# STM32MP157 register map
File version: 1.6
CPU: CM4 r0p1, little endian, no MPU, FPU, 4 interrupt priority bits
Registers are 32-bit, read-write, reset 0x0 unless marked. A register's access mark holds for its fields unless they carry their own. Offsets are from the block's base; [hi:lo] are bit positions; 'fields as' and 'values as' point back to an identical list.

## TIM12
Base 0x40006000
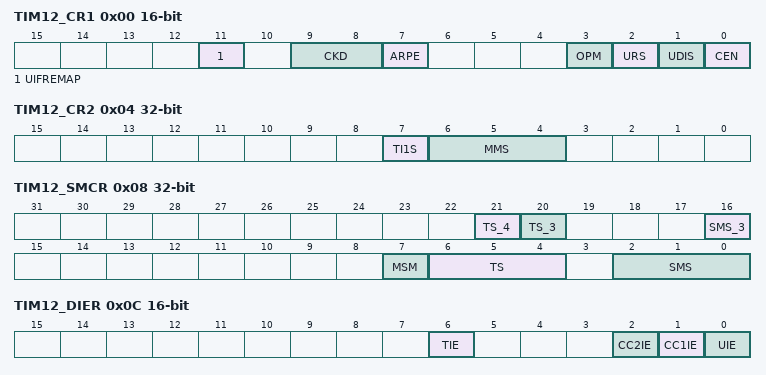
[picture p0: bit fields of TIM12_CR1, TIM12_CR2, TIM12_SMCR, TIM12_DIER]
0x00 TIM12_CR1 16-bit — TIM12 control register 1
  [11] UIFREMAP, [9:8] CKD, [7] ARPE, [3] OPM, [2] URS, [1] UDIS, [0] CEN
0x04 TIM12_CR2 — TIM12 control register 2
  [7] TI1S, [6:4] MMS
0x08 TIM12_SMCR — TIM12 slave mode control register
  [21] TS_4, [20] TS_3, [16] SMS_3, [7] MSM, [6:4] TS, [2:0] SMS
0x0C TIM12_DIER 16-bit — TIM12 interrupt enable register
  [6] TIE, [2] CC2IE, [1] CC1IE, [0] UIE
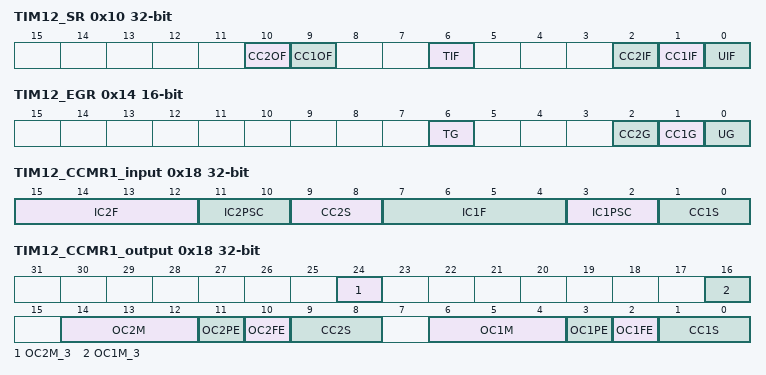
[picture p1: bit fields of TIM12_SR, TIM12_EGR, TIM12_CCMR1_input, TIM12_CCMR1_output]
0x10 TIM12_SR — TIM12 status register
  [10] CC2OF, [9] CC1OF, [6] TIF, [2] CC2IF, [1] CC1IF, [0] UIF
0x14 TIM12_EGR 16-bit wo — TIM12 event generation register
  [6] TG, [2] CC2G, [1] CC1G, [0] UG
0x18 TIM12_CCMR1_input — TIM12 capture/compare mode register 1
  [15:12] IC2F, [11:10] IC2PSC, [9:8] CC2S, [7:4] IC1F, [3:2] IC1PSC, [1:0] CC1S
0x18 TIM12_CCMR1_output (alternate view of TIM12_CCMR1_input) — TIM12 capture/compare mode register 1
  [24] OC2M_3
  [16] OC1M_3
  [14:12] OC2M
  [11] OC2PE
  [10] OC2FE
  [9:8] CC2S
  [6:4] OC1M
  [3] OC1PE — OC1FE
  [2] OC1FE
  [1:0] CC1S
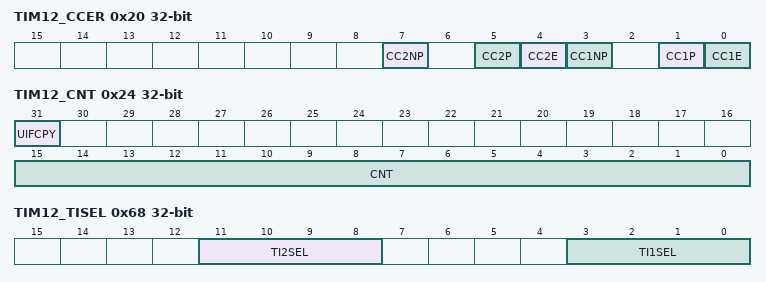
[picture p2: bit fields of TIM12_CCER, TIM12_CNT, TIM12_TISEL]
0x20 TIM12_CCER — TIM12 capture/compare enable register
  [7] CC2NP, [5] CC2P, [4] CC2E, [3] CC1NP, [1] CC1P, [0] CC1E
0x24 TIM12_CNT access per field — TIM12 counter
  [31] UIFCPY ro, [15:0] CNT rw
0x28 TIM12_PSC 16-bit — TIM12 prescaler
0x2C TIM12_ARR 16-bit reset 0xFFFF — TIM12 auto-reload register
0x34 TIM12_CCR1 16-bit — TIM12 capture/compare register 1
0x38 TIM12_CCR2 16-bit — TIM12 capture/compare register 2
0x68 TIM12_TISEL — TIM12 timer input selection register
  [11:8] TI2SEL, [3:0] TI1SEL

## TIM13
Base 0x40007000
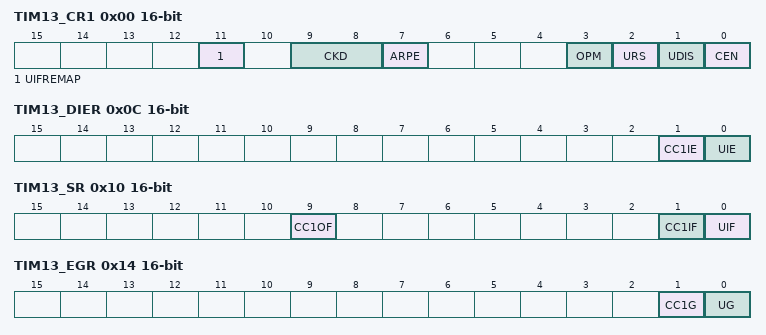
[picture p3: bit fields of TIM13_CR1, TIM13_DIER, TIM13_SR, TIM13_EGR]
0x00 TIM13_CR1 16-bit — TIM13 control register 1
  [11] UIFREMAP, [9:8] CKD, [7] ARPE, [3] OPM, [2] URS, [1] UDIS, [0] CEN
0x0C TIM13_DIER 16-bit — TIM13 Interrupt enable register
  [1] CC1IE, [0] UIE
0x10 TIM13_SR 16-bit — TIM13 status register
  [9] CC1OF, [1] CC1IF, [0] UIF
0x14 TIM13_EGR 16-bit wo — TIM13 event generation register
  [1] CC1G, [0] UG
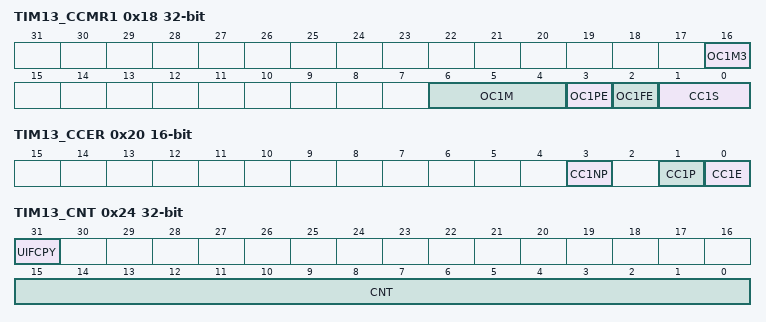
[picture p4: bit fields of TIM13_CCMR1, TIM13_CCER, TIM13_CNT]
0x18 TIM13_CCMR1 — The channels can be used in input (capture mode) or in output (compare mode). The direction of a channel is defined by configuring the corresponding CCxS bits. All the other bits of this register have a different function in input and in output mode. For a given bit, OCxx describes its function when the channel is configured in output, ICxx describes its function when the channel is configured in input. So one must take care that the same bit can have a different meaning for the input stage and for the output stage. Output compare mode
  [16] OC1M3, [6:4] OC1M, [3] OC1PE, [2] OC1FE, [1:0] CC1S
0x20 TIM13_CCER 16-bit — TIM13 capture/compare enable register
  [3] CC1NP, [1] CC1P, [0] CC1E
0x24 TIM13_CNT — TIM13 counter
  [31] UIFCPY, [15:0] CNT
0x28 TIM13_PSC 16-bit — TIM13 prescaler
0x2C TIM13_ARR 16-bit reset 0xFFFF — TIM13 auto-reload register
0x34 TIM13_CCR1 16-bit — TIM13 capture/compare register 1
0x68 TIM13_TISEL 16-bit — TIM13 timer input selection register
  [3:0] TI1SEL

## TIM14
Base 0x40008000
Registers as TIM13 (with TIM13 read as TIM14).

## TIM15
Base 0x44006000
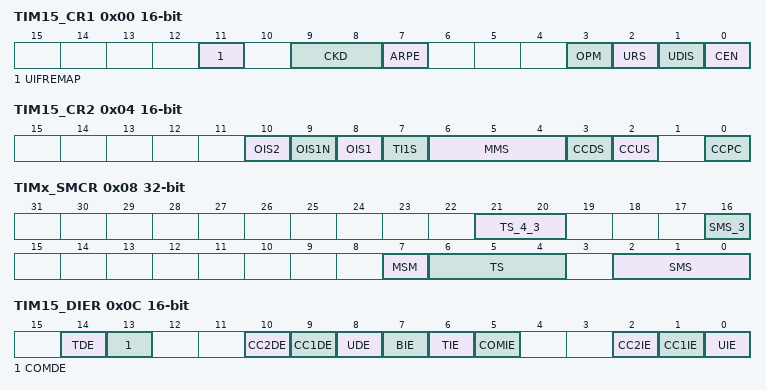
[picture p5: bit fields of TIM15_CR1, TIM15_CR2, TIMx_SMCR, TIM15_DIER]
0x00 TIM15_CR1 16-bit — TIM15 control register 1
  [11] UIFREMAP, [9:8] CKD, [7] ARPE, [3] OPM, [2] URS, [1] UDIS, [0] CEN
0x04 TIM15_CR2 16-bit — TIM15 control register 2
  [10] OIS2, [9] OIS1N, [8] OIS1, [7] TI1S, [6:4] MMS, [3] CCDS, [2] CCUS, [0] CCPC
0x08 TIMx_SMCR — slave mode control register
  [21:20] TS_4_3 — Trigger selection
  [16] SMS_3 — Slave mode selection - bit 3
  [7] MSM — Master/Slave mode
  [6:4] TS — Trigger selection
  [2:0] SMS — Slave mode selection
0x0C TIM15_DIER 16-bit — TIM15 DMA/interrupt enable register
  [14] TDE, [13] COMDE, [10] CC2DE, [9] CC1DE, [8] UDE, [7] BIE, [6] TIE, [5] COMIE, [2] CC2IE, [1] CC1IE, [0] UIE
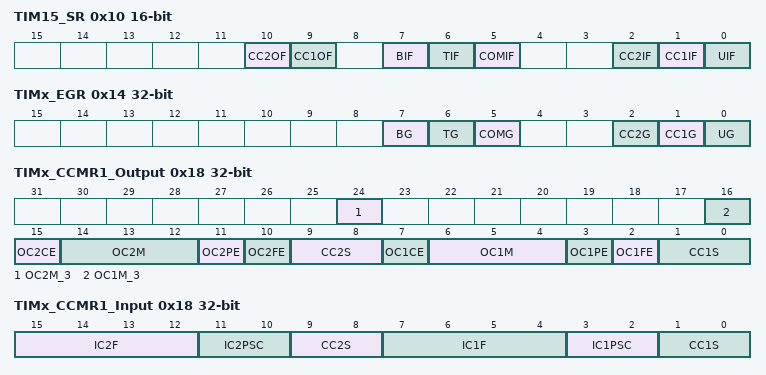
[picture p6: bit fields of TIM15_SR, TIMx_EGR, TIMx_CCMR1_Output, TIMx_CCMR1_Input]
0x10 TIM15_SR 16-bit — TIM15 status register
  [10] CC2OF, [9] CC1OF, [7] BIF, [6] TIF, [5] COMIF, [2] CC2IF, [1] CC1IF, [0] UIF
0x14 TIMx_EGR wo — event generation register
  [7] BG
  [6] TG — Trigger generation
  [5] COMG
  [2] CC2G — Capture/compare 2 generation
  [1] CC1G — Capture/compare 1 generation
  [0] UG — Update generation
0x18 TIMx_CCMR1_Output — capture/compare mode register 1 (output mode)
  [24] OC2M_3 — Output Compare 2 mode - bit 3
  [16] OC1M_3 — Output Compare 1 mode - bit 3
  [15] OC2CE — Output compare 2 clear enable
  [14:12] OC2M — Output compare 2 mode
  [11] OC2PE — Output compare 2 preload enable
  [10] OC2FE — Output compare 2 fast enable
  [9:8] CC2S — Capture/Compare 2 selection
  [7] OC1CE — Output compare 1 clear enable
  [6:4] OC1M — Output compare 1 mode
  [3] OC1PE — Output compare 1 preload enable
  [2] OC1FE — Output compare 1 fast enable
  [1:0] CC1S — Capture/Compare 1 selection
0x18 TIMx_CCMR1_Input (alternate view of TIMx_CCMR1_Output) — capture/compare mode register 1 (input mode)
  [15:12] IC2F — Input capture 2 filter
  [11:10] IC2PSC — Input capture 2 prescaler
  [9:8] CC2S — Capture/compare 2 selection
  [7:4] IC1F — Input capture 1 filter
  [3:2] IC1PSC — Input capture 1 prescaler
  [1:0] CC1S — Capture/Compare 1 selection
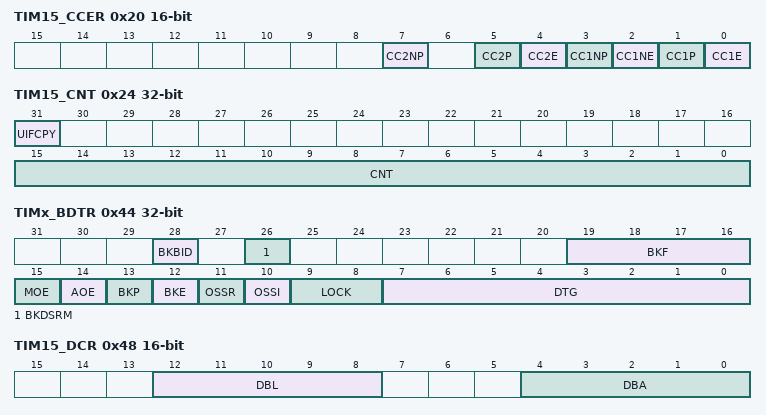
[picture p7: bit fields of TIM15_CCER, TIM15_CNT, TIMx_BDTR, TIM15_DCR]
0x20 TIM15_CCER 16-bit — TIM15 capture/compare enable register
  [7] CC2NP, [5] CC2P, [4] CC2E, [3] CC1NP, [2] CC1NE, [1] CC1P, [0] CC1E
0x24 TIM15_CNT — TIM15 counter
  [31] UIFCPY ro, [15:0] CNT
0x28 TIM15_PSC 16-bit — TIM15 prescaler
0x2C TIM15_ARR 16-bit reset 0xFFFF — TIM15 auto-reload register
0x30 TIM15_RCR 16-bit — TIM15 repetition counter register
  [7:0] REP
0x34 TIM15_CCR1 16-bit — TIM15 capture/compare register 1
0x38 TIM15_CCR2 16-bit — TIM15 capture/compare register 2
0x44 TIMx_BDTR — As the bits BK2BID, BKBID, BK2DSRM, BKDSRM, BK2P, BK2E, BK2F[3:0], BKF[3:0], AOE, BKP, BKE, OSSI, OSSR and DTG[7:0] can be write-locked depending on the LOCK configuration, it can be necessary to configure all of them during the first write access to the TIMx_BDTR register.
  [28] BKBID, [26] BKDSRM, [19:16] BKF, [15] MOE, [14] AOE, [13] BKP, [12] BKE, [11] OSSR, [10] OSSI, [9:8] LOCK, [7:0] DTG
0x48 TIM15_DCR 16-bit — TIM15 DMA control register
  [12:8] DBL, [4:0] DBA
0x4C TIM15_DMAR 16-bit — TIM15 DMA address for full transfer
  [15:0] DMAB
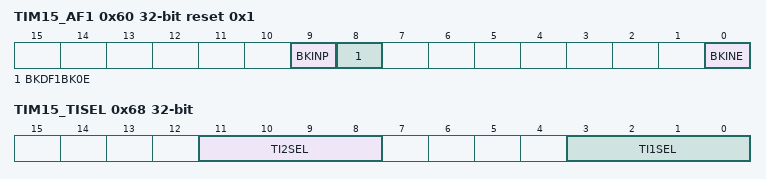
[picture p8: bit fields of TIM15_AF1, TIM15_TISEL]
0x60 TIM15_AF1 reset 0x1 — TIM15 alternate register 1
  [9] BKINP, [8] BKDF1BK0E, [0] BKINE
0x68 TIM15_TISEL — TIM15 input selection register
  [11:8] TI2SEL, [3:0] TI1SEL

## TIM16
Base 0x44007000
Same registers: TIM17 0x44008000
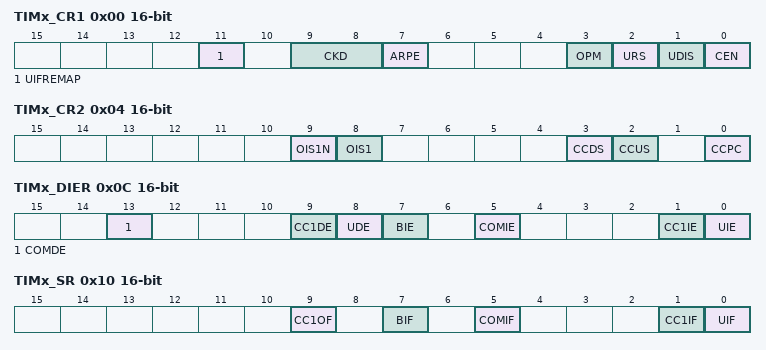
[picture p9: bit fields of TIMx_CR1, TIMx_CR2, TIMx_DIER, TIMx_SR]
0x00 TIMx_CR1 16-bit — TIM16/TIM17 control register 1
  [11] UIFREMAP, [9:8] CKD, [7] ARPE, [3] OPM, [2] URS, [1] UDIS, [0] CEN
0x04 TIMx_CR2 16-bit — TIM16/TIM17 control register 2
  [9] OIS1N, [8] OIS1, [3] CCDS, [2] CCUS, [0] CCPC
0x0C TIMx_DIER 16-bit — TIM16/TIM17 DMA/interrupt enable register
  [13] COMDE, [9] CC1DE, [8] UDE, [7] BIE, [5] COMIE, [1] CC1IE, [0] UIE
0x10 TIMx_SR 16-bit — TIM16/TIM17 status register
  [9] CC1OF, [7] BIF, [5] COMIF, [1] CC1IF, [0] UIF
0x14 TIMx_EGR wo — event generation register
  [0] UG — Update generation
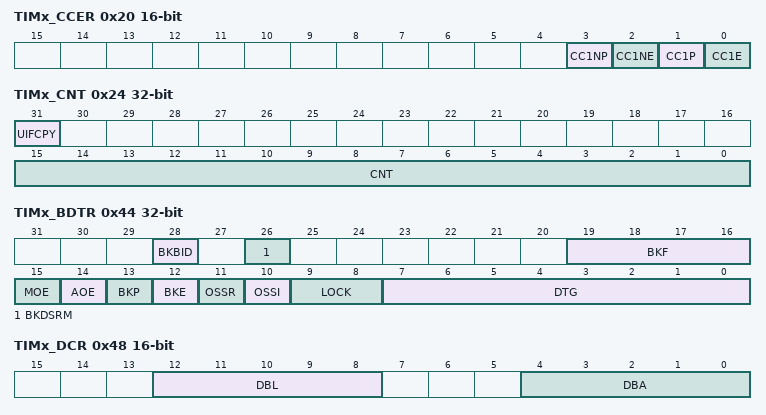
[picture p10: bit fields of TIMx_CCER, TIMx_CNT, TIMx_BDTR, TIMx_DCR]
0x20 TIMx_CCER 16-bit — TIM16/TIM17 capture/compare enable register
  [3] CC1NP, [2] CC1NE, [1] CC1P, [0] CC1E
0x24 TIMx_CNT — TIM16/TIM17 counter
  [31] UIFCPY ro, [15:0] CNT
0x28 TIMx_PSC 16-bit — TIM16/TIM17 prescaler
0x2C TIMx_ARR 16-bit reset 0xFFFF — TIM16/TIM17 auto-reload register
0x30 TIMx_RCR 16-bit — TIM16/TIM17 repetition counter register
  [7:0] REP
0x34 TIMx_CCR1 16-bit — TIM16/TIM17 capture/compare register 1
0x44 TIMx_BDTR — As the BKBID, BKDSRM, BKF[3:0], AOE, BKP, BKE, OSSI, OSSR and DTG[7:0] bits may be write-locked depending on the LOCK configuration, it may be necessary to configure all of them during the first write access to the TIMx_BDTR register.
  [28] BKBID, [26] BKDSRM, [19:16] BKF, [15] MOE, [14] AOE, [13] BKP, [12] BKE, [11] OSSR, [10] OSSI, [9:8] LOCK, [7:0] DTG
0x48 TIMx_DCR 16-bit — TIM16/TIM17 DMA control register
  [12:8] DBL, [4:0] DBA
0x4C TIMx_DMAR 16-bit — TIM16/TIM17 DMA address for full transfer
  [15:0] DMAB
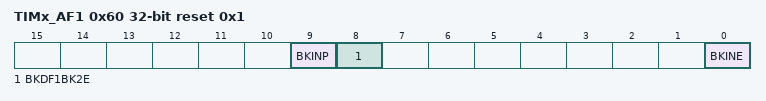
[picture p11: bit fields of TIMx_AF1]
0x60 TIMx_AF1 reset 0x1 — TIM17 alternate function register 1
  [9] BKINP, [8] BKDF1BK2E, [0] BKINE
0x68 TIMx_TISEL — TIM17 input selection register
  [3:0] TI1SEL

## USBPHYC
Base 0x5A006000
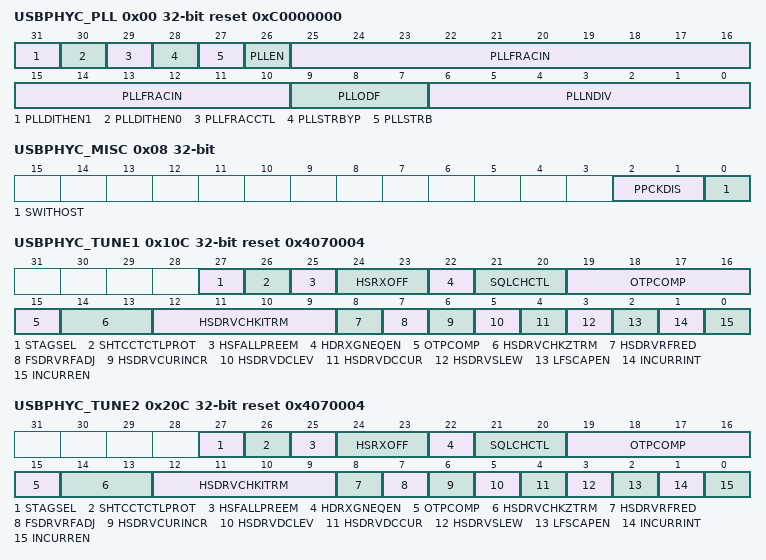
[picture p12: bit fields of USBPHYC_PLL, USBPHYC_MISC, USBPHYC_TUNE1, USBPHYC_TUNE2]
0x00 USBPHYC_PLL reset 0xC0000000 — This register is used to control the PLL of the HS PHY.
  [31] PLLDITHEN1, [30] PLLDITHEN0, [29] PLLFRACCTL, [28] PLLSTRBYP, [27] PLLSTRB, [26] PLLEN, [25:10] PLLFRACIN, [9:7] PLLODF, [6:0] PLLNDIV
0x08 USBPHYC_MISC — This register is used to control the switch between controllers for the HS PHY.
  [2:1] PPCKDIS, [0] SWITHOST
0x10C USBPHYC_TUNE1 reset 0x4070004 — This register is used to control the tune interface of the HS PHY, port #x.
  [27] STAGSEL, [26] SHTCCTCTLPROT, [25] HSFALLPREEM, [24:23] HSRXOFF, [22] HDRXGNEQEN, [21:20] SQLCHCTL, [19:15] OTPCOMP, [14:13] HSDRVCHKZTRM, [12:9] HSDRVCHKITRM, [8] HSDRVRFRED, [7] FSDRVRFADJ, [6] HSDRVCURINCR, [5] HSDRVDCLEV, [4] HSDRVDCCUR, [3] HSDRVSLEW, [2] LFSCAPEN, [1] INCURRINT, [0] INCURREN
0x20C USBPHYC_TUNE2 reset 0x4070004 — This register is used to control the tune interface of the HS PHY, port #x.
  fields as USBPHYC_TUNE1
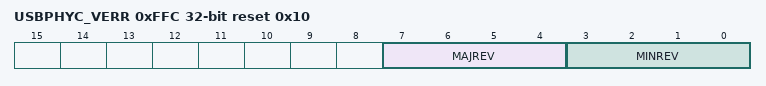
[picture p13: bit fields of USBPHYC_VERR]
0xFFC USBPHYC_VERR ro reset 0x10 — This register defines the version of this IP.
  [7:4] MAJREV, [3:0] MINREV

## VREFBUF
Base 0x50025000
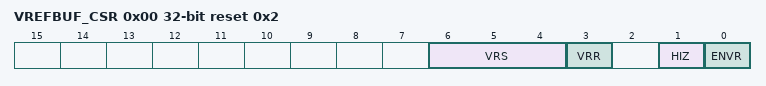
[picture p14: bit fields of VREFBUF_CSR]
0x00 VREFBUF_CSR access per field reset 0x2 — VREFBUF control and status register
  [6:4] VRS rw, [3] VRR ro, [1] HIZ rw, [0] ENVR rw
0x04 VREFBUF_CCR — VREFBUF calibration control register
  [5:0] TRIM

## WWDG1
Base 0x4000A000
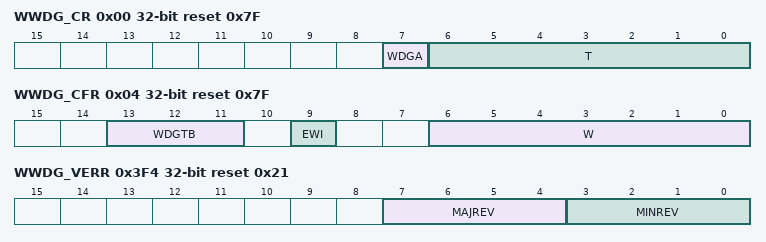
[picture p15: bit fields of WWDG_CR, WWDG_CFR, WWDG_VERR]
0x00 WWDG_CR reset 0x7F — Control register
  [7] WDGA, [6:0] T
0x04 WWDG_CFR reset 0x7F — Configuration register
  [13:11] WDGTB, [9] EWI, [6:0] W
0x08 WWDG_SR — Status register
  [0] EWIF
0x3F0 WWDG_HWCFGR ro reset 0xFFF — WWDG hardware configuration register
  [15:0] PREDIV
0x3F4 WWDG_VERR ro reset 0x21 — WWDG version register
  [7:4] MAJREV, [3:0] MINREV
0x3F8 WWDG_IPIDR ro reset 0x120051 — WWDG ID register
  [31:0] ID
0x3FC WWDG_SIDR ro reset 0xA3C5DD01 — WWDG size ID register
  [31:0] SID
